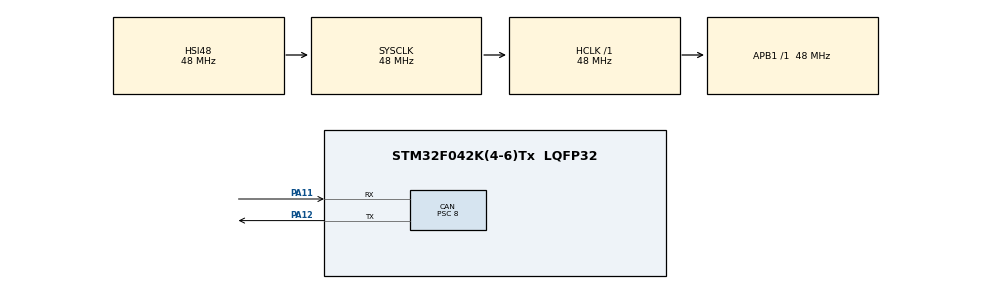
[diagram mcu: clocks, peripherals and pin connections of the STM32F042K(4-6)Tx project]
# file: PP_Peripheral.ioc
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CAN.BS1=CAN_BS1_6TQ
CAN.BS2=CAN_BS2_5TQ
CAN.CalculateBaudRate=500000
CAN.CalculateTimeBit=2000
CAN.CalculateTimeQuantum=166.66666666666666
CAN.Prescaler=8
Mcu.Family=STM32F0
Mcu.Name=STM32F042K(4-6)Tx
Mcu.Package=LQFP32
PA11.Mode=CAN_Activate
PA11.Signal=CAN_RX
PA12.Mode=CAN_Activate
PA12.Signal=CAN_TX
PA13.Mode=Serial_Wire
PA13.Signal=SYS_SWDIO
PA14.Mode=Serial_Wire
PA14.Signal=SYS_SWCLK
ProjectManager.HeapSize=0x200
ProjectManager.StackSize=0x400
ProjectManager.TargetToolchain=MDK-ARM V5
RCC.AHBFreq_Value=48000000
RCC.APB1Freq_Value=48000000
RCC.APB1TimFreq_Value=48000000
RCC.HCLKFreq_Value=48000000
RCC.SYSCLKFreq_VALUE=48000000
RCC.SYSCLKSource=RCC_SYSCLKSOURCE_HSI48
board=custom

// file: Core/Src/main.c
/* USER CODE BEGIN Header */
/**
  ******************************************************************************
  * @file           : main.c
  * @brief          : Main program body
  ******************************************************************************
  * @attention
  *
  * Copyright (c) 2022 STMicroelectronics.
  * All rights reserved.
  *
  * This software is licensed under terms that can be found in the LICENSE file
  * in the root directory of this software component.
  * If no LICENSE file comes with this software, it is provided AS-IS.
  *
  ******************************************************************************
  */
/* USER CODE END Header */
#include "main.h"
#include "can.h"
#include "gpio.h"

/* USER CODE BEGIN PV */
static CAN_TxHeaderTypeDef        TxMessage;    //CAN发送的消息的消息头
static CAN_RxHeaderTypeDef        RxMessage;    //CAN接收的消息的消息头
/* USER CODE END PV */

void SystemClock_Config(void);
/* USER CODE BEGIN PFP */
static void CANFilter_Config(void);
void CAN_Send(uint8_t orderD);
/* USER CODE END PFP */

int main(void)
{

  /* MCU Configuration--------------------------------------------------------*/

  /* Reset of all peripherals, Initializes the Flash interface and the Systick. */
  HAL_Init();

  /* Configure the system clock */
  SystemClock_Config();

  /* Initialize all configured peripherals */
  MX_GPIO_Init();
  MX_CAN_Init();
  /* USER CODE BEGIN 2 */
	/* 1. CAN Filter Config */
	CANFilter_Config();
	/* 2. CAN Start */
	if(HAL_CAN_Start(&hcan) != HAL_OK)
	{
		Error_Handler();
	}
  /* 3. Enable CAN RX Interrupt */
	if(HAL_CAN_ActivateNotification(&hcan, CAN_IT_RX_FIFO0_MSG_PENDING) != HAL_OK)
	{
		Error_Handler();
	}

  /* USER CODE END 2 */

  /* Infinite loop */
  /* USER CODE BEGIN WHILE */
  while (1)
  {
		CAN_Send(0x02);
		HAL_Delay(100);
    /* USER CODE END WHILE */

  }
}

void SystemClock_Config(void)
{
  RCC_OscInitTypeDef RCC_OscInitStruct = {0};
  RCC_ClkInitTypeDef RCC_ClkInitStruct = {0};

  /** Initializes the RCC Oscillators according to the specified parameters
  * in the RCC_OscInitTypeDef structure.
  */
  RCC_OscInitStruct.OscillatorType = RCC_OSCILLATORTYPE_HSI48;
  RCC_OscInitStruct.HSI48State = RCC_HSI48_ON;
  RCC_OscInitStruct.PLL.PLLState = RCC_PLL_NONE;
  if (HAL_RCC_OscConfig(&RCC_OscInitStruct) != HAL_OK)
  {
    Error_Handler();
  }
  /** Initializes the CPU, AHB and APB buses clocks
  */
  RCC_ClkInitStruct.ClockType = RCC_CLOCKTYPE_HCLK|RCC_CLOCKTYPE_SYSCLK
                              |RCC_CLOCKTYPE_PCLK1;
  RCC_ClkInitStruct.SYSCLKSource = RCC_SYSCLKSOURCE_HSI48;
  RCC_ClkInitStruct.AHBCLKDivider = RCC_SYSCLK_DIV1;
  RCC_ClkInitStruct.APB1CLKDivider = RCC_HCLK_DIV1;

  if (HAL_RCC_ClockConfig(&RCC_ClkInitStruct, FLASH_LATENCY_1) != HAL_OK)
  {
    Error_Handler();
  }
}

/* USER CODE BEGIN 4 */
/**
  * @brief CAN过滤器配置函数（掩码全为零，不进行过滤）
  * @retval None
  */
static void CANFilter_Config(void)
{
    CAN_FilterTypeDef  sFilterConfig;

    sFilterConfig.FilterBank = 0;                       //CAN过滤器编号，范围0-27
    sFilterConfig.FilterMode = CAN_FILTERMODE_IDMASK;   //CAN过滤器模式，掩码模式或列表模式
    sFilterConfig.FilterScale = CAN_FILTERSCALE_32BIT;  //CAN过滤器尺度，16位或32位
    sFilterConfig.FilterIdHigh = 0x000 << 5;			      //32位下，存储要过滤ID的高16位
    sFilterConfig.FilterIdLow = 0x0000;					        //32位下，存储要过滤ID的低16位
    sFilterConfig.FilterMaskIdHigh = 0x0000;			      //掩码模式下，存储的是掩码
    sFilterConfig.FilterMaskIdLow = 0x0000;
    sFilterConfig.FilterFIFOAssignment = 0;				      //报文通过过滤器的匹配后，存储到哪个FIFO
    sFilterConfig.FilterActivation = ENABLE;    		    //激活过滤器
    sFilterConfig.SlaveStartFilterBank = 0;

    if (HAL_CAN_ConfigFilter(&hcan, &sFilterConfig) != HAL_OK) {
        Error_Handler();
    }
}

/**
  * @brief CAN发送数据函数
  * @retval None
  */
void CAN_Send(uint8_t orderD)
{
	uint8_t dataO[1];
	dataO[0] = orderD;

	uint32_t TxMailbox;
	TxMessage.IDE = CAN_ID_STD;     //设置ID类型，标准模式
	TxMessage.StdId = 0x0000;        //设置ID号，标识符，可进行过滤
	TxMessage.RTR = CAN_RTR_DATA;   //设置传送数据帧
	TxMessage.DLC = 1;              //设置数据长度

	if (HAL_CAN_AddTxMessage(&hcan, &TxMessage, dataO, &TxMailbox) != HAL_OK)
	{
		Error_Handler();
  }
}

/**
  * @brief CAN接收中断处理函数
  * @retval None
  */
void HAL_CAN_RxFifo0MsgPendingCallback(CAN_HandleTypeDef *hcan)
{
	uint8_t  data[8];

	if(HAL_CAN_GetRxMessage(hcan, CAN_RX_FIFO0, &RxMessage, data) == HAL_OK)
	{

	}
}
/* USER CODE END 4 */

void Error_Handler(void)
{
  __disable_irq();
  while (1)
  {
  }
}
